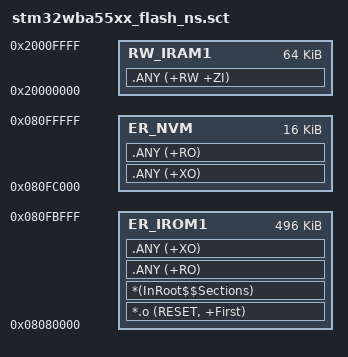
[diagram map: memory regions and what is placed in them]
; *************************************************************
; *** Scatter-Loading Description File generated by uVision ***
; *************************************************************

LR_IROM1 0x08080000 0x0007c000  {    ; load region size_region
  ER_IROM1 0x08080000 0x0007c000  {  ; load address = execution address
   *.o (RESET, +First)
   *(InRoot$$Sections)
   .ANY (+RO)
   .ANY (+XO)
  }
;***region***;
;***endregion***;
  RW_IRAM1 0x20000000 0x00010000  {  ; RW data
   .ANY (+RW +ZI)
  }
}

/*-Start of  regions- Auto-generated By STM32CubeMX-*/
LR_NVM 0x080fc000 0x00004000  {  ; load_region size_region
  ER_NVM 0x080fc000 0x00004000  {  ; load address = excetion address
   .ANY (+XO)
   .ANY (+RO)
  }
}


